# nrf52811 register map
Vendor: Nordic Semiconductor; Series: nrf52; File version: 1
CPU: CM4 r0p1, little endian, MPU, no FPU, 3 interrupt priority bits
Registers are 32-bit, read-write, reset 0x0 unless marked. A register's access mark holds for its fields unless they carry their own. Offsets are from the block's base; [hi:lo] are bit positions; {n}, {i} and the like mark numbered series; 'fields as' and 'values as' point back to an identical list.

## AAR — Accelerated Address Resolver
Base 0x4000F000
0x00 TASKS_START wo — Start resolving addresses based on IRKs specified in the IRK data structure
  [0] TASKS_START
    1=Trigger task
0x08 TASKS_STOP wo — Stop resolving addresses
  [0] TASKS_STOP
    1=Trigger task
0x100 EVENTS_END — Address resolution procedure complete
  [0] EVENTS_END
    0=NotGenerated (Event not generated); 1=Generated (Event generated)
0x104 EVENTS_RESOLVED — Address resolved
  [0] EVENTS_RESOLVED
    values as EVENTS_END.EVENTS_END
0x108 EVENTS_NOTRESOLVED — Address not resolved
  [0] EVENTS_NOTRESOLVED
    values as EVENTS_END.EVENTS_END
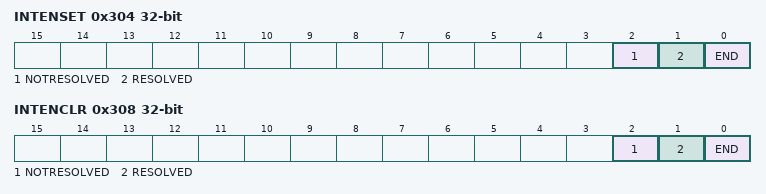
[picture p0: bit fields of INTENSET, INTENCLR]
0x304 INTENSET — Enable interrupt
  [all] fields
    on read: 0=Disabled (Read: Disabled); 1=Enabled (Read: Enabled) | on write: 1=Set (Enable)
  [2] NOTRESOLVED — Write '1' to enable interrupt for event NOTRESOLVED
  [1] RESOLVED — Write '1' to enable interrupt for event RESOLVED
  [0] END — Write '1' to enable interrupt for event END
0x308 INTENCLR — Disable interrupt
  [all] fields
    on read: 0=Disabled (Read: Disabled); 1=Enabled (Read: Enabled) | on write: 1=Clear (Disable)
  [2] NOTRESOLVED — Write '1' to disable interrupt for event NOTRESOLVED
  [1] RESOLVED — Write '1' to disable interrupt for event RESOLVED
  [0] END — Write '1' to disable interrupt for event END
0x400 STATUS ro — Resolution status
  [3:0] STATUS — The IRK that was used last time an address was resolved
0x500 ENABLE — Enable AAR
  [1:0] ENABLE — Enable or disable AAR
    0=Disabled; 3=Enabled
0x504 NIRK reset 0x1 — Number of IRKs
  [4:0] NIRK — Number of Identity root keys available in the IRK data structure
0x508 IRKPTR — Pointer to IRK data structure
  [31:0] IRKPTR — Pointer to the IRK data structure
0x510 ADDRPTR — Pointer to the resolvable address
  [31:0] ADDRPTR — Pointer to the resolvable address (6-bytes)
0x514 SCRATCHPTR — Pointer to data area used for temporary storage
  [31:0] SCRATCHPTR — Pointer to a scratch data area used for temporary storage during resolution. A space of minimum 3 bytes must be reserved.

## WDT — Watchdog Timer
Base 0x40010000
0x00 TASKS_START wo — Start the watchdog
  [0] TASKS_START
    1=Trigger task
0x100 EVENTS_TIMEOUT — Watchdog timeout
  [0] EVENTS_TIMEOUT
    0=NotGenerated (Event not generated); 1=Generated (Event generated)
0x304 INTENSET — Enable interrupt
  [0] TIMEOUT — Write '1' to enable interrupt for event TIMEOUT
    on read: 0=Disabled (Read: Disabled); 1=Enabled (Read: Enabled) | on write: 1=Set (Enable)
0x308 INTENCLR — Disable interrupt
  [0] TIMEOUT — Write '1' to disable interrupt for event TIMEOUT
    on read: 0=Disabled (Read: Disabled); 1=Enabled (Read: Enabled) | on write: 1=Clear (Disable)
0x400 RUNSTATUS ro
  [0] RUNSTATUS — Indicates whether or not the watchdog is running
    0=NotRunning (Watchdog not running); 1=Running (Watchdog is running)
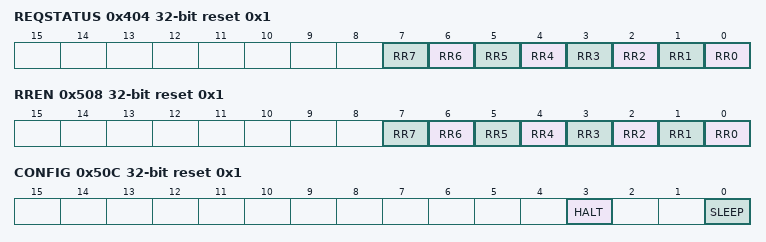
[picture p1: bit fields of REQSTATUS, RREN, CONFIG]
0x404 REQSTATUS ro reset 0x1 — Request status
  [n] RR{n} (n=0..7) — Request status for RR[{n}] register
    0=DisabledOrRequested (RR[{n}] register is not enabled, or are already requesting reload); 1=EnabledAndUnrequested (RR[{n}] register is enabled, and are not yet requesting reload)
0x504 CRV reset 0xFFFFFFFF — Counter reload value
  [31:0] CRV — Counter reload value in number of cycles of the 32.768 kHz clock
0x508 RREN reset 0x1 — Enable register for reload request registers
  [n] RR{n} (n=0..7) — Enable or disable RR[{n}] register
    0=Disabled (Disable RR[{n}] register); 1=Enabled (Enable RR[{n}] register)
0x50C CONFIG reset 0x1 — Configuration register
  [3] HALT — Configure the watchdog to either be paused, or kept running, while the CPU is halted by the debugger
    0=Pause watchdog while the CPU is halted by the debugger; 1=Run (Keep the watchdog running while the CPU is halted by the debugger)
  [0] SLEEP — Configure the watchdog to either be paused, or kept running, while the CPU is sleeping
    0=Pause watchdog while the CPU is sleeping; 1=Run (Keep the watchdog running while the CPU is sleeping)
{0x600+4i} RR[{i}] (i=0..7) wo — Description collection: Reload request n
  [31:0] RR — Reload request register
    0x6E524635=Reload (Value to request a reload of the watchdog timer)
